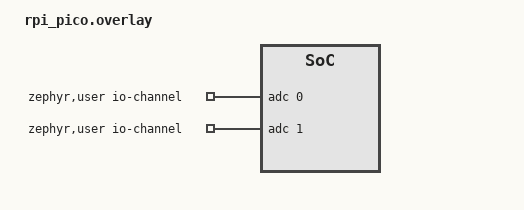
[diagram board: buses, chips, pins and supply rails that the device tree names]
/*
 * SPDX-License-Identifier: Apache-2.0
 *
 * Copyright (c) 2022 TOKITA Hiroshi <tokita.hiroshi@fujitsu.com>
 */

/ {
       zephyr,user {
               io-channels = <&adc 0>, <&adc 1>;
       };
};
